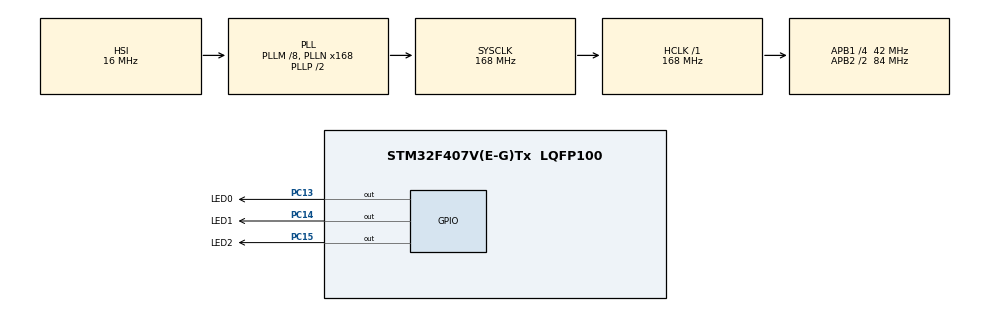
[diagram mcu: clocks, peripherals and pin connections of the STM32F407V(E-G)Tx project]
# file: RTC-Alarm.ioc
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Mcu.Family=STM32F4
Mcu.Name=STM32F407V(E-G)Tx
Mcu.Package=LQFP100
NVIC.PriorityGroup=NVIC_PRIORITYGROUP_4
NVIC.RTC_Alarm_IRQn=true\:0\:0\:false\:false\:true\:true\:true
NVIC.RTC_WKUP_IRQn=true\:0\:0\:false\:false\:true\:true\:true
PC13-ANTI_TAMP.GPIO_Label=LED0
PC13-ANTI_TAMP.PinState=GPIO_PIN_SET
PC13-ANTI_TAMP.Signal=GPIO_Output
PC14-OSC32_IN.GPIO_Label=LED1
PC14-OSC32_IN.PinState=GPIO_PIN_SET
PC14-OSC32_IN.Signal=GPIO_Output
PC15-OSC32_OUT.GPIO_Label=LED2
PC15-OSC32_OUT.PinState=GPIO_PIN_SET
PC15-OSC32_OUT.Signal=GPIO_Output
ProjectManager.HeapSize=0x200
ProjectManager.StackSize=0x400
ProjectManager.TargetToolchain=MDK-ARM V5.27
RCC.48MHZClocksFreq_Value=84000000
RCC.AHBFreq_Value=168000000
RCC.APB1CLKDivider=RCC_HCLK_DIV4
RCC.APB1Freq_Value=42000000
RCC.APB1TimFreq_Value=84000000
RCC.APB2CLKDivider=RCC_HCLK_DIV2
RCC.APB2Freq_Value=84000000
RCC.APB2TimFreq_Value=168000000
RCC.CortexFreq_Value=168000000
RCC.HCLKFreq_Value=168000000
RCC.HSE_VALUE=25000000
RCC.HSI_VALUE=16000000
RCC.LSE_VALUE=32768
RCC.PLLM=8
RCC.PLLN=168
RCC.SYSCLKFreq_VALUE=168000000
RCC.SYSCLKSource=RCC_SYSCLKSOURCE_PLLCLK
RCC.VCOOutputFreq_Value=336000000
RTC.Alarm=RTC_ALARM_A
RTC.AlarmDateWeekDay=10
RTC.AlarmDateWeekDay_B=10
RTC.Alarm_B=RTC_ALARM_B
RTC.AsynchPrediv=124
RTC.Date=10
RTC.Format=RTC_FORMAT_BIN
RTC.Hours=6
RTC.Hours_A=6
RTC.Hours_B=6
RTC.Minutes=52
RTC.Minutes_A=52
RTC.Minutes_B=52
RTC.Seconds=20
RTC.Seconds_A=25
RTC.Seconds_B=30
RTC.WakeUpClock=RTC_WAKEUPCLOCK_CK_SPRE_16BITS
RTC.WeekDay=RTC_WEEKDAY_WEDNESDAY
RTC.Year=24
VP_RTC_VS_RTC_Activate.Mode=RTC_Enabled
VP_RTC_VS_RTC_Alarm_A_Intern.Mode=Alarm A
VP_RTC_VS_RTC_Alarm_B_Intern.Mode=Alarm B
VP_RTC_VS_RTC_Calendar.Mode=RTC_Calendar
VP_RTC_VS_RTC_WakeUp_intern.Mode=WakeUp
board=custom

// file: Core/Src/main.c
/* USER CODE BEGIN Header */
/**
  ******************************************************************************
  * @file           : main.c
  * @brief          : Main program body
  ******************************************************************************
  * @attention
  *
  * <h2><center>&copy; Copyright (c) 2024 STMicroelectronics.
  * All rights reserved.</center></h2>
  *
  * This software component is licensed by ST under BSD 3-Clause license,
  * the "License"; You may not use this file except in compliance with the
  * License. You may obtain a copy of the License at:
  *                        opensource.org/licenses/BSD-3-Clause
  *
  ******************************************************************************
  */
/* USER CODE END Header */
#include "main.h"
#include "rtc.h"
#include "gpio.h"

/* USER CODE BEGIN Includes */
#include "ALCD.h"
/* USER CODE END Includes */

void SystemClock_Config(void);

int main(void)
{
  /* USER CODE BEGIN 1 */
  RTC_DateTypeDef date;
  RTC_TimeTypeDef time;
  /* USER CODE END 1 */

  /* MCU Configuration--------------------------------------------------------*/

  /* Reset of all peripherals, Initializes the Flash interface and the Systick. */
  HAL_Init();

  /* Configure the system clock */
  SystemClock_Config();

  /* Initialize all configured peripherals */
  MX_GPIO_Init();
  MX_RTC_Init();
  /* USER CODE BEGIN 2 */
  ALCD_init(16, 2);
  ALCD_clear();
  /* USER CODE END 2 */

  /* Infinite loop */
  /* USER CODE BEGIN WHILE */
  while (1)
  {
    HAL_RTC_GetTime(&hrtc, &time, RTC_FORMAT_BIN);
    HAL_RTC_GetDate(&hrtc, &date, RTC_FORMAT_BIN);

    ALCD_printfXY(4, 0, "%02u:%02u:%02u", time.Hours, time.Minutes, time.Seconds);
    ALCD_printfXY(4, 1, "%02u/%02u/%02u", date.Year, date.Month, date.Date);

    // Optional
    HAL_Delay(1000);
    /* USER CODE END WHILE */

  }
}

void SystemClock_Config(void)
{
  RCC_OscInitTypeDef RCC_OscInitStruct = {0};
  RCC_ClkInitTypeDef RCC_ClkInitStruct = {0};
  RCC_PeriphCLKInitTypeDef PeriphClkInitStruct = {0};

  /** Configure the main internal regulator output voltage
  */
  __HAL_RCC_PWR_CLK_ENABLE();
  __HAL_PWR_VOLTAGESCALING_CONFIG(PWR_REGULATOR_VOLTAGE_SCALE1);
  /** Initializes the RCC Oscillators according to the specified parameters
  * in the RCC_OscInitTypeDef structure.
  */
  RCC_OscInitStruct.OscillatorType = RCC_OSCILLATORTYPE_HSI|RCC_OSCILLATORTYPE_LSI;
  RCC_OscInitStruct.HSIState = RCC_HSI_ON;
  RCC_OscInitStruct.HSICalibrationValue = RCC_HSICALIBRATION_DEFAULT;
  RCC_OscInitStruct.LSIState = RCC_LSI_ON;
  RCC_OscInitStruct.PLL.PLLState = RCC_PLL_ON;
  RCC_OscInitStruct.PLL.PLLSource = RCC_PLLSOURCE_HSI;
  RCC_OscInitStruct.PLL.PLLM = 8;
  RCC_OscInitStruct.PLL.PLLN = 168;
  RCC_OscInitStruct.PLL.PLLP = RCC_PLLP_DIV2;
  RCC_OscInitStruct.PLL.PLLQ = 4;
  if (HAL_RCC_OscConfig(&RCC_OscInitStruct) != HAL_OK)
  {
    Error_Handler();
  }
  /** Initializes the CPU, AHB and APB buses clocks
  */
  RCC_ClkInitStruct.ClockType = RCC_CLOCKTYPE_HCLK|RCC_CLOCKTYPE_SYSCLK
                              |RCC_CLOCKTYPE_PCLK1|RCC_CLOCKTYPE_PCLK2;
  RCC_ClkInitStruct.SYSCLKSource = RCC_SYSCLKSOURCE_PLLCLK;
  RCC_ClkInitStruct.AHBCLKDivider = RCC_SYSCLK_DIV1;
  RCC_ClkInitStruct.APB1CLKDivider = RCC_HCLK_DIV4;
  RCC_ClkInitStruct.APB2CLKDivider = RCC_HCLK_DIV2;

  if (HAL_RCC_ClockConfig(&RCC_ClkInitStruct, FLASH_LATENCY_5) != HAL_OK)
  {
    Error_Handler();
  }
  PeriphClkInitStruct.PeriphClockSelection = RCC_PERIPHCLK_RTC;
  PeriphClkInitStruct.RTCClockSelection = RCC_RTCCLKSOURCE_LSI;
  if (HAL_RCCEx_PeriphCLKConfig(&PeriphClkInitStruct) != HAL_OK)
  {
    Error_Handler();
  }
}

/* USER CODE BEGIN 4 */
void HAL_RTC_AlarmAEventCallback(RTC_HandleTypeDef* hrtc) {
  HAL_GPIO_TogglePin(LED0_GPIO_Port, LED0_Pin);
}

void HAL_RTCEx_AlarmBEventCallback(RTC_HandleTypeDef* hrtc) {
  HAL_GPIO_TogglePin(LED1_GPIO_Port, LED1_Pin);
}

void HAL_RTCEx_WakeUpTimerEventCallback(RTC_HandleTypeDef* hrtc) {
  HAL_GPIO_TogglePin(LED2_GPIO_Port, LED2_Pin);
}

/* USER CODE END 4 */

void Error_Handler(void)
{
  __disable_irq();
  while (1)
  {
  }
}

/************************ (C) COPYRIGHT STMicroelectronics *****END OF FILE****/
